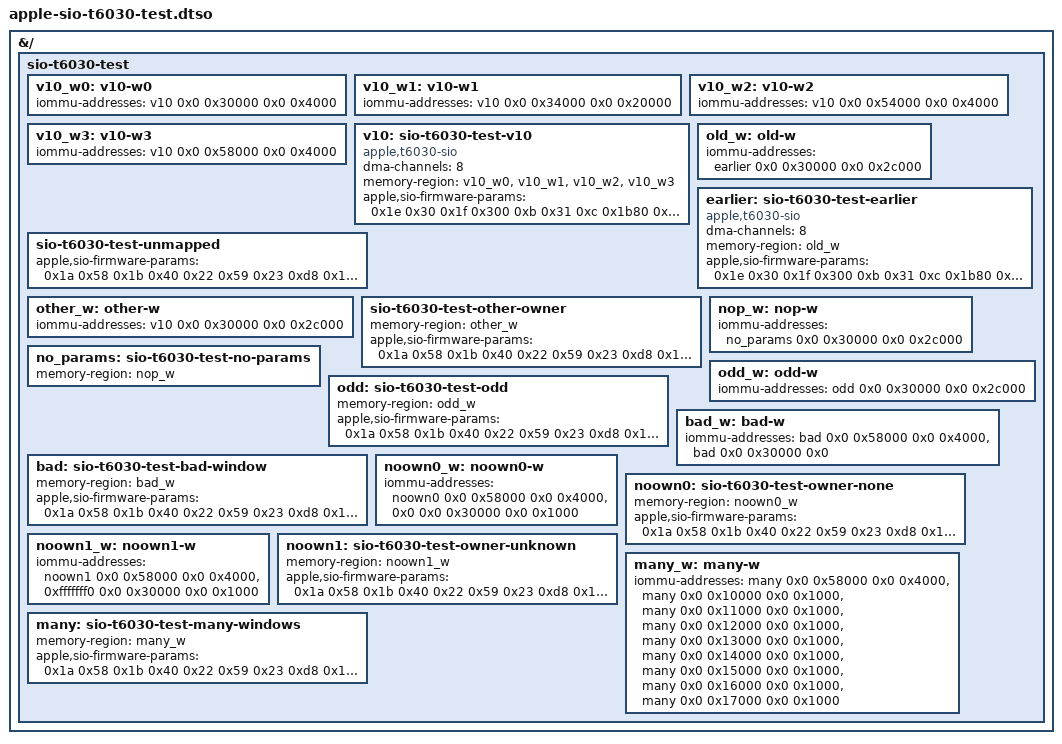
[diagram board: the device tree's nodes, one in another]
// SPDX-License-Identifier: GPL-2.0-only OR MIT
/dts-v1/;
/plugin/;

/*
 * T6030 SIO nodes as boot loaders leave them: parameters in apple,sio-firmware-params and the
 * firmware data mapped through memory regions with iommu-addresses. The v10 node carries the
 * tables a T6030-aware loader builds; the earlier node the tables of a loader without
 * protocol-10 support, in the same windows. The container is not a bus, so nothing binds to
 * them; the probe test calls the probe itself, on a device without registers.
 */
&{/} {
	sio-t6030-test {
		#address-cells = <2>;
		#size-cells = <2>;

		v10_w0: v10-w0 { iommu-addresses = <&v10 0x0 0x30000 0x0 0x4000>; };
		v10_w1: v10-w1 { iommu-addresses = <&v10 0x0 0x34000 0x0 0x20000>; };
		v10_w2: v10-w2 { iommu-addresses = <&v10 0x0 0x54000 0x0 0x4000>; };
		v10_w3: v10-w3 { iommu-addresses = <&v10 0x0 0x58000 0x0 0x4000>; };

		v10: sio-t6030-test-v10 {
			compatible = "apple,t6030-sio", "apple,sio";
			dma-channels = <8>;
			memory-region = <&v10_w0 &v10_w1 &v10_w2 &v10_w3>;
			apple,sio-firmware-params = <0x1e 0x30 0x1f 0x300 0xb 0x31 0xc 0x1b80
						     0xf 0x34 0x10 0x1e000 0x30d 0x54 0x30e 0x4000
						     0x1a 0x58 0x1b 0x40 0x22 0x59 0x23 0xd8
						     0x1c 0x5a 0x1d 0x48>;
		};

		old_w: old-w { iommu-addresses = <&earlier 0x0 0x30000 0x0 0x2c000>; };

		earlier: sio-t6030-test-earlier {
			compatible = "apple,t6030-sio", "apple,sio";
			dma-channels = <8>;
			memory-region = <&old_w>;
			apple,sio-firmware-params = <0x1e 0x30 0x1f 0x300 0xb 0x31 0xc 0x1b80
						     0xf 0x34 0x10 0x1e000 0x30d 0x54 0x30e 0x4000
						     0x1a 0x58 0x1b 0x40 0x22 0x59 0x23 0xa0
						     0x1c 0x5a 0x1d 0x40>;
		};

		sio-t6030-test-unmapped {
			apple,sio-firmware-params = <0x1a 0x58 0x1b 0x40 0x22 0x59 0x23 0xd8
						     0x1c 0x5a 0x1d 0x48>;
		};

		other_w: other-w { iommu-addresses = <&v10 0x0 0x30000 0x0 0x2c000>; };

		sio-t6030-test-other-owner {
			memory-region = <&other_w>;
			apple,sio-firmware-params = <0x1a 0x58 0x1b 0x40 0x22 0x59 0x23 0xd8
						     0x1c 0x5a 0x1d 0x48>;
		};

		nop_w: nop-w { iommu-addresses = <&no_params 0x0 0x30000 0x0 0x2c000>; };

		no_params: sio-t6030-test-no-params {
			memory-region = <&nop_w>;
		};

		odd_w: odd-w { iommu-addresses = <&odd 0x0 0x30000 0x0 0x2c000>; };

		odd: sio-t6030-test-odd {
			memory-region = <&odd_w>;
			apple,sio-firmware-params = <0x1a 0x58 0x1b 0x40 0x22 0x59 0x23 0xd8
						     0x1c 0x5a 0x1d>;
		};

		/* A window entry cut short, after the window that holds the tables */
		bad_w: bad-w { iommu-addresses = <&bad 0x0 0x58000 0x0 0x4000>, <&bad 0x0 0x30000 0x0>; };

		bad: sio-t6030-test-bad-window {
			memory-region = <&bad_w>;
			apple,sio-firmware-params = <0x1a 0x58 0x1b 0x40 0x22 0x59 0x23 0xd8
						     0x1c 0x5a 0x1d 0x48>;
		};

		/*
		 * An entry whose owner phandle does not resolve (none, or no such
		 * node), after the window that holds the tables
		 */
		noown0_w: noown0-w { iommu-addresses = <&noown0 0x0 0x58000 0x0 0x4000>,
							 <0x0 0x0 0x30000 0x0 0x1000>; };

		noown0: sio-t6030-test-owner-none {
			memory-region = <&noown0_w>;
			apple,sio-firmware-params = <0x1a 0x58 0x1b 0x40 0x22 0x59 0x23 0xd8
						     0x1c 0x5a 0x1d 0x48>;
		};

		noown1_w: noown1-w { iommu-addresses = <&noown1 0x0 0x58000 0x0 0x4000>,
							 <0xfffffff0 0x0 0x30000 0x0 0x1000>; };

		noown1: sio-t6030-test-owner-unknown {
			memory-region = <&noown1_w>;
			apple,sio-firmware-params = <0x1a 0x58 0x1b 0x40 0x22 0x59 0x23 0xd8
						     0x1c 0x5a 0x1d 0x48>;
		};

		/* More windows than any loader maps; the first one holds the tables */
		many_w: many-w {
			iommu-addresses = <&many 0x0 0x58000 0x0 0x4000>, <&many 0x0 0x10000 0x0 0x1000>,
					  <&many 0x0 0x11000 0x0 0x1000>, <&many 0x0 0x12000 0x0 0x1000>,
					  <&many 0x0 0x13000 0x0 0x1000>, <&many 0x0 0x14000 0x0 0x1000>,
					  <&many 0x0 0x15000 0x0 0x1000>, <&many 0x0 0x16000 0x0 0x1000>,
					  <&many 0x0 0x17000 0x0 0x1000>;
		};

		many: sio-t6030-test-many-windows {
			memory-region = <&many_w>;
			apple,sio-firmware-params = <0x1a 0x58 0x1b 0x40 0x22 0x59 0x23 0xd8
						     0x1c 0x5a 0x1d 0x48>;
		};
	};
};
